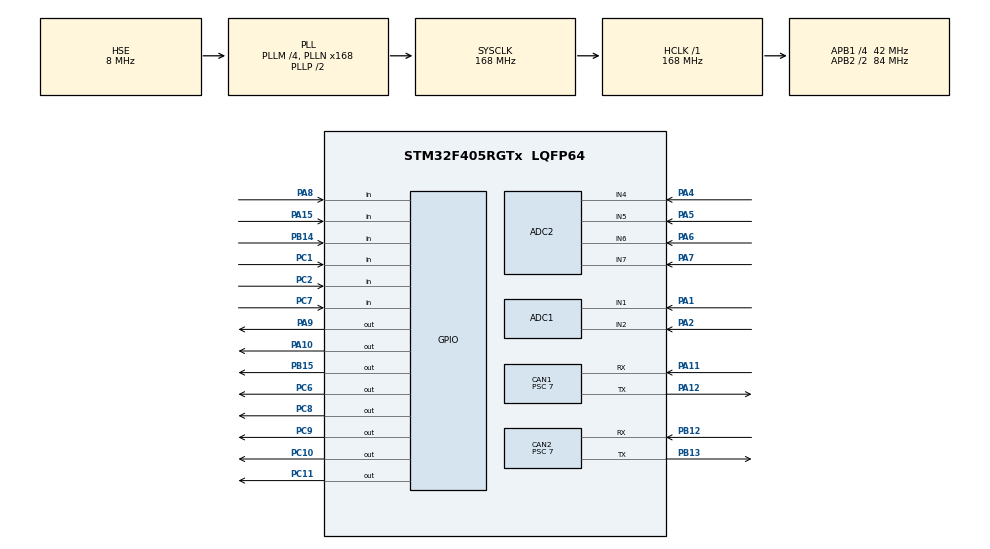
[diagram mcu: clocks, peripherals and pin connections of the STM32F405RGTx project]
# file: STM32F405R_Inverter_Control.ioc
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ADC1.Channel-4\#ChannelRegularConversion=ADC_CHANNEL_2
ADC1.NbrOfConversionFlag=1
ADC1.Rank-4\#ChannelRegularConversion=1
ADC1.SamplingTime-4\#ChannelRegularConversion=ADC_SAMPLETIME_3CYCLES
ADC1.master=1
ADC2.Channel-0\#ChannelRegularConversion=ADC_CHANNEL_4
ADC2.NbrOfConversionFlag=1
ADC2.Rank-0\#ChannelRegularConversion=1
ADC2.SamplingTime-0\#ChannelRegularConversion=ADC_SAMPLETIME_3CYCLES
CAN1.BS1=CAN_BS1_8TQ
CAN1.BS2=CAN_BS2_3TQ
CAN1.CalculateBaudRate=500000
CAN1.CalculateTimeBit=1999.99
CAN1.CalculateTimeQuantum=166.66666666666669
CAN1.Prescaler=7
CAN2.BS1=CAN_BS1_8TQ
CAN2.BS2=CAN_BS2_3TQ
CAN2.CalculateBaudRate=500000
CAN2.CalculateTimeBit=1999.99
CAN2.CalculateTimeQuantum=166.66666666666669
CAN2.Prescaler=7
Mcu.Family=STM32F4
Mcu.Name=STM32F405RGTx
Mcu.Package=LQFP64
NVIC.PriorityGroup=NVIC_PRIORITYGROUP_4
PA1.Signal=ADCx_IN1
PA10.Signal=GPIO_Output
PA11.Mode=CAN_Activate
PA11.Signal=CAN1_RX
PA12.Mode=CAN_Activate
PA12.Signal=CAN1_TX
PA13.Mode=Trace_Asynchronous_SW
PA13.Signal=SYS_JTMS-SWDIO
PA14.Mode=Trace_Asynchronous_SW
PA14.Signal=SYS_JTCK-SWCLK
PA15.Signal=GPIO_Input
PA2.Signal=ADCx_IN2
PA4.Signal=ADCx_IN4
PA5.Signal=ADCx_IN5
PA6.Signal=ADCx_IN6
PA7.Signal=ADCx_IN7
PA8.Signal=GPIO_Input
PA9.Signal=GPIO_Output
PB12.Mode=CAN_Activate
PB12.Signal=CAN2_RX
PB13.Mode=CAN_Activate
PB13.Signal=CAN2_TX
PB14.Signal=GPIO_Input
PB15.Signal=GPIO_Output
PB3.Mode=Trace_Asynchronous_SW
PB3.Signal=SYS_JTDO-SWO
PC1.Signal=GPIO_Input
PC10.Signal=GPIO_Output
PC11.Signal=GPIO_Output
PC2.Signal=GPIO_Input
PC6.Signal=GPIO_Output
PC7.Signal=GPIO_Input
PC8.Signal=GPIO_Output
PC9.Signal=GPIO_Output
PH0-OSC_IN.Mode=HSE-External-Oscillator
PH0-OSC_IN.Signal=RCC_OSC_IN
PH1-OSC_OUT.Mode=HSE-External-Oscillator
PH1-OSC_OUT.Signal=RCC_OSC_OUT
ProjectManager.HeapSize=0x200
ProjectManager.StackSize=0x400
ProjectManager.TargetToolchain=STM32CubeIDE
RCC.48MHZClocksFreq_Value=48000000
RCC.AHBFreq_Value=168000000
RCC.APB1CLKDivider=RCC_HCLK_DIV4
RCC.APB1Freq_Value=42000000
RCC.APB1TimFreq_Value=84000000
RCC.APB2CLKDivider=RCC_HCLK_DIV2
RCC.APB2Freq_Value=84000000
RCC.APB2TimFreq_Value=168000000
RCC.CortexFreq_Value=168000000
RCC.HCLKFreq_Value=168000000
RCC.HSE_VALUE=8000000
RCC.HSI_VALUE=16000000
RCC.LSE_VALUE=32768
RCC.PLLM=4
RCC.PLLN=168
RCC.PLLQ=7
RCC.PLLSourceVirtual=RCC_PLLSOURCE_HSE
RCC.RCC_RTC_Clock_Source=RCC_RTCCLKSOURCE_LSE
RCC.RCC_RTC_Clock_SourceVirtual=RCC_RTCCLKSOURCE_LSE
RCC.RCC_RTC_Clock_Source_FROM_HSE=RCC_RTCCLKSOURCE_HSE_DIV31
RCC.SYSCLKFreq_VALUE=168000000
RCC.SYSCLKSource=RCC_SYSCLKSOURCE_PLLCLK
RCC.VCOOutputFreq_Value=336000000
SH.ADCx_IN1.0=ADC1_IN1,IN1
SH.ADCx_IN2.0=ADC1_IN2,IN2
SH.ADCx_IN4.0=ADC2_IN4,IN4
SH.ADCx_IN5.0=ADC2_IN5,IN5
SH.ADCx_IN6.0=ADC2_IN6,IN6
SH.ADCx_IN7.0=ADC2_IN7,IN7
board=custom

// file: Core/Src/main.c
/* USER CODE BEGIN Header */
/**
  ******************************************************************************
  * @file           : main.c
  * @brief          : Main program body
  ******************************************************************************
  * @attention
  *
  * <h2><center>&copy; Copyright (c) 2021 STMicroelectronics.
  * All rights reserved.</center></h2>
  *
  * This software component is licensed by ST under BSD 3-Clause license,
  * the "License"; You may not use this file except in compliance with the
  * License. You may obtain a copy of the License at:
  *                        opensource.org/licenses/BSD-3-Clause
  *
  ******************************************************************************
  */
/* USER CODE END Header */
#include "main.h"
#include "adc.h"
#include "can.h"
#include "gpio.h"

/* USER CODE BEGIN Includes */
#include "GAS_Scheduler.h"
/* USER CODE END Includes */

/* USER CODE BEGIN PD */
#define TRUE 1
#define FALSE 0
/* USER CODE END PD */

/* USER CODE BEGIN PV */
volatile uint32_t flag_10ms = FALSE;
volatile uint32_t flag_100ms = FALSE;
volatile uint32_t counter_100ms = 0;
/* USER CODE END PV */

void SystemClock_Config(void);

int main(void)
{

  /* MCU Configuration--------------------------------------------------------*/

  /* Reset of all peripherals, Initializes the Flash interface and the Systick. */
  HAL_Init();

  /* Configure the system clock */
  SystemClock_Config();

  /* Initialize all configured peripherals */
  MX_GPIO_Init();
  MX_ADC1_Init();
  MX_CAN2_Init();
  MX_CAN1_Init();
  MX_ADC2_Init();
  /* USER CODE BEGIN 2 */
  GAS_Scheduler_init();
  /* USER CODE END 2 */

  /* Infinite loop */
  while (1)
  {

    /* USER CODE BEGIN 3 */
	  GAS_Scheduler();
  }
  /* USER CODE END 3 */
}

void SystemClock_Config(void)
{
  RCC_OscInitTypeDef RCC_OscInitStruct = {0};
  RCC_ClkInitTypeDef RCC_ClkInitStruct = {0};

  /** Configure the main internal regulator output voltage
  */
  __HAL_RCC_PWR_CLK_ENABLE();
  __HAL_PWR_VOLTAGESCALING_CONFIG(PWR_REGULATOR_VOLTAGE_SCALE1);
  /** Initializes the RCC Oscillators according to the specified parameters
  * in the RCC_OscInitTypeDef structure.
  */
  RCC_OscInitStruct.OscillatorType = RCC_OSCILLATORTYPE_HSE;
  RCC_OscInitStruct.HSEState = RCC_HSE_ON;
  RCC_OscInitStruct.PLL.PLLState = RCC_PLL_ON;
  RCC_OscInitStruct.PLL.PLLSource = RCC_PLLSOURCE_HSE;
  RCC_OscInitStruct.PLL.PLLM = 4;
  RCC_OscInitStruct.PLL.PLLN = 168;
  RCC_OscInitStruct.PLL.PLLP = RCC_PLLP_DIV2;
  RCC_OscInitStruct.PLL.PLLQ = 7;
  if (HAL_RCC_OscConfig(&RCC_OscInitStruct) != HAL_OK)
  {
    Error_Handler();
  }
  /** Initializes the CPU, AHB and APB buses clocks
  */
  RCC_ClkInitStruct.ClockType = RCC_CLOCKTYPE_HCLK|RCC_CLOCKTYPE_SYSCLK
                              |RCC_CLOCKTYPE_PCLK1|RCC_CLOCKTYPE_PCLK2;
  RCC_ClkInitStruct.SYSCLKSource = RCC_SYSCLKSOURCE_PLLCLK;
  RCC_ClkInitStruct.AHBCLKDivider = RCC_SYSCLK_DIV1;
  RCC_ClkInitStruct.APB1CLKDivider = RCC_HCLK_DIV4;
  RCC_ClkInitStruct.APB2CLKDivider = RCC_HCLK_DIV2;

  if (HAL_RCC_ClockConfig(&RCC_ClkInitStruct, FLASH_LATENCY_5) != HAL_OK)
  {
    Error_Handler();
  }
}

void Error_Handler(void)
{
  __disable_irq();
  while (1)
  {
  }
}

/************************ (C) COPYRIGHT STMicroelectronics *****END OF FILE****/
